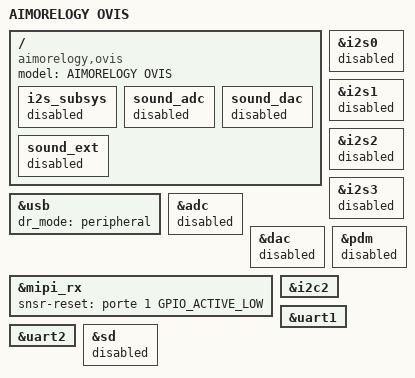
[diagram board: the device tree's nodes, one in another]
/dts-v1/;
#include "cv184x_base_arm.dtsi"
#include "cv184x_asic_bga.dtsi"
#include "cv184x_asic_spinand.dtsi"
#include "cv184x_default_memmap.dtsi"

/ {
	model = "AIMORELOGY OVIS";
	compatible = "aimorelogy,ovis", "cvitek,cv184x";

	i2s_subsys {
		status = "disabled";
	};
	sound_adc {
		status = "disabled";
	};
	sound_dac {
		status = "disabled";
	};
	sound_ext {
		status = "disabled";
	};
};

&usb {
	dr_mode = "peripheral";
};

&i2s0 {
	status = "disabled";
};
&i2s1 {
	status = "disabled";
};
&i2s2 {
	status = "disabled";
};
&i2s3 {
	status = "disabled";
};
&adc {
	status = "disabled";
};
&dac {
	status = "disabled";
};
&pdm {
	status = "disabled";
};

&mipi_rx {
	snsr-reset = <&porte 1 GPIO_ACTIVE_LOW>;
};

&i2c2 {
	status = "okay";
};

&uart1 {
	status = "okay";
};

&uart2 {
	status = "okay";
};

&sd {
	status = "disabled";
};
